# S32R372 register map
Vendor: Freescale Semiconductor, Inc.; Series: Qorivva; File version: 1.6
Registers are 32-bit, read-write, reset 0x0 unless marked. A register's access mark holds for its fields unless they carry their own. Offsets are from the block's base; [hi:lo] are bit positions; {n}, {i} and the like mark numbered series; 'fields as' and 'values as' point back to an identical list.

## SEMA42
Base 0xFC03C000; register names take the prefix SEMA42_
{0x0+i} GATE{i} (i=0..15) 8-bit
  [3:0] GTFSM — Gate Finite State Machine.
    0=The gate is unlocked (free); {v}=The gate has been locked by processor {v-1} (v=1..15)
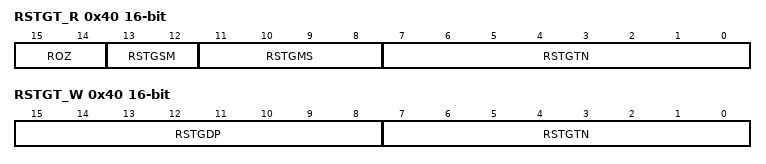
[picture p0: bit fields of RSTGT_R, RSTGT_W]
0x40 RSTGT_R 16-bit ro (SEMA42 view) — Reset Gate Read
  [15:14] ROZ — This field always returns the value 0 when read.
  [13:12] RSTGSM — Reset Gate Finite State Machine
    0=Idle, waiting for the first data pattern write; 1=Waiting for the second data pattern write; 2=The 2-write sequence has completed. Generate the specified gate reset(s). After the reset is performed, this machine returns to the idle (waiting for first data pattern write) state. The "01" state persists for only one clock cycle. Software cannot observe this state.; 3=This state encoding is never used and therefore reserved
  [11:8] RSTGMS — Reset Gate Bus Master
  [7:0] RSTGTN — Reset Gate Number
0x40 RSTGT_W 16-bit wo (SEMA42 view) — Reset Gate Write
  [15:8] RSTGDP — Reset Gate Data Pattern
  [7:0] RSTGTN — Reset Gate Number

## INTC
Base 0xFC040000; register names take the prefix INTC_
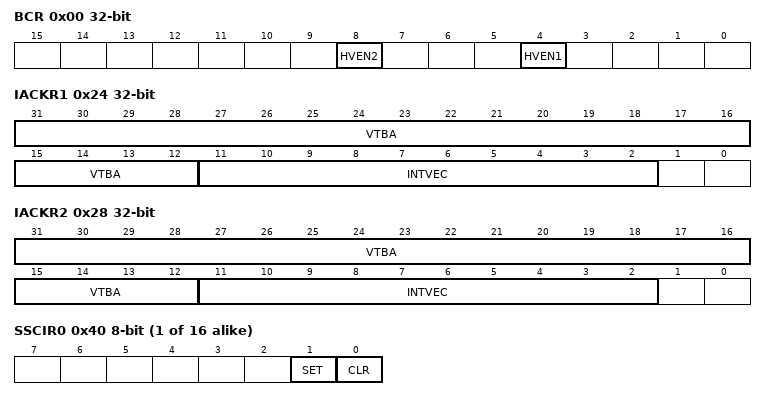
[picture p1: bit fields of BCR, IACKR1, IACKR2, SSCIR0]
0x00 BCR — INTC Block Configuration Register
  [8] HVEN2 — Hardware vector enable for processor 2
    0=Software vector mode; 1=Hardware vector mode
  [4] HVEN1 — Hardware vector enable for processor 1
    0=Software vector mode; 1=Hardware vector mode
0x14 CPR1 reset 0x1F — INTC Current Priority Register for Processor 1
  [4:0] PRI — Priority of the currently executing ISR, according to the field values 31 (highest priority) down to 0 (lowest priority)
0x18 CPR2 reset 0x1F — INTC Current Priority Register for Processor 2
  fields as CPR1
0x24 IACKR1 — INTC Interrupt Acknowledge Register for Processor 1
  [31:12] VTBA — Vector table base address. Can be the base address of a vector table of addresses of ISRs.
  [11:2] INTVEC ro — Interrupt vector
0x28 IACKR2 — INTC Interrupt Acknowledge Register for Processor 2
  fields as IACKR1
0x34 EOIR1 wo — INTC End Of Interrupt Register for Processor 1
  [31:0] EOI — End of Interrupt
0x38 EOIR2 wo — INTC End Of Interrupt Register for Processor 2
  [31:0] EOI — End of Interrupt
{0x40+i} SSCIR{i} (i=0..15) 8-bit — INTC Software Set/Clear Interrupt Register
  [1] SET wo — Set flag bits
  [0] CLR — Clear flag bits
    0=Interrupt request not pending within INTC; 1=Interrupt request pending within INTC
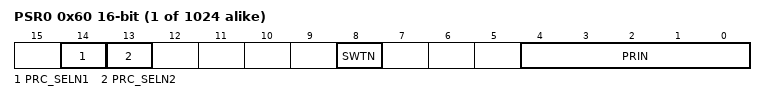
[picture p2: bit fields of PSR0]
{0x60+2i} PSR{i} (i=0..1023) 16-bit — INTC Priority Select Register
  [14] PRC_SELN1 — Processor select 1
    0=Interrupt request not sent to processor 1; 1=Interrupt request sent to processor 1
  [13] PRC_SELN2 — Processor select 2
    0=Interrupt request not sent to processor 2; 1=Interrupt request sent to processor 2
  [8] SWTN — This bit is only available in PSRs that do not correspond to the SSCIRs
  [4:0] PRIN — Priority select
0x1034 MMRC1 — INTC Monitor Mode Register 1
  [1:0] MM — Monitor Mode. Controls whether the INTC monitors the latency or interrupt handler time
    0=Disabled; 1=IACK - Interrupt Acknowledge - timer is active from assertion of IRQ until interrupt acknowledge. An error is signaled if timer exceeds the programmed interrupt latency and the programmed interrupt latency is non-zero.; 2=EOI - End Of Interrupt - timer is active from assertion of IRQ until the end of the interrupt handler. The timer will continue to run even if interrupt handler is preempted. An error is signaled if timer exceeds the programmed interrupt latency and the programmed interrupt latency is non-zero.; 3=SW - Software - timer is active from assertion of IRQ until the end of the interrupt handler unless it is preempted. A return from interrupt will start the timer if it is the timer associated with the active IRQ. No error is signaled; rather software can read the timer at any time.
{0x1038+4i} HIPRI{i}C1 (i=0..2) — INTC HIPRI Register
  [9:0] IRQ — Select the IRQ to monitor (input the hex value of the IRQ)
{0x1048+4i} LAT{i}C1 (i=0..2) — INTC LAT Register
  [23:0] LAT — Select the maximum number of INTC clock cycles allowed for the monitored IRQ.
{0x1058+4i} TIMER{i}C1 (i=0..2) — INTC Timer Register
  [23:0] TIMER — Timer is used to count the number of INTC clock cycles up to 24 bits of resolution.
0x1068 MMRC2 — INTC Monitor Mode Register 2
  fields as MMRC1
{0x106C+4i} HIPRI{i}C2 (i=0..2) — INTC HIPRI Register
  fields as HIPRI0C1
{0x107C+4i} LAT{i}C2 (i=0..2) — INTC LAT Register
  fields as LAT0C1
{0x108C+4i} TIMER{i}C2 (i=0..2) — INTC Timer Register
  fields as TIMER0C1
